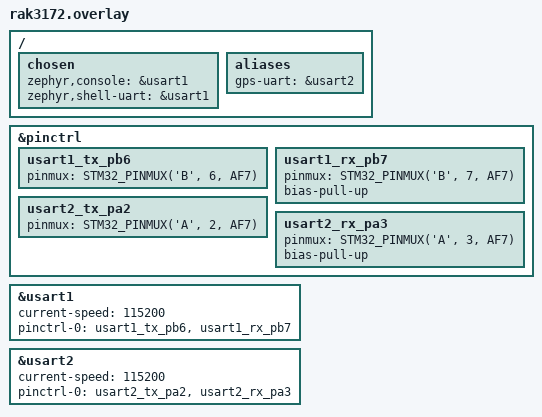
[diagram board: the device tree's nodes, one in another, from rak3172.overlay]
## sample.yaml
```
# Copyright (c) 2023 Trackunit Corporation
# SPDX-License-Identifier: Apache-2.0

sample:
  name: GNSS sample
tests:
  sample.drivers.gnss:
    tags:
      - drivers
      - gnss
    filter: dt_alias_exists("gnss")
    integration_platforms:
      - mimxrt1062_fmurt6
```

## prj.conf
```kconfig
# UART support for both console and GPS
CONFIG_SERIAL=y
CONFIG_UART_INTERRUPT_DRIVEN=y
CONFIG_CONSOLE=y
CONFIG_UART_CONSOLE=y

# Logging
CONFIG_LOG=y
CONFIG_LOG_BACKEND_UART=y

# System
CONFIG_MAIN_STACK_SIZE=4096
CONFIG_HEAP_MEM_POOL_SIZE=4096
```

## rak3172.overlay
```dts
/*
 * Dual UART setup:
 * USART1 (PB6/PB7): PC Console at 115200 baud
 * USART2 (PA2/PA3): GPS Module at 115200 baud
 */

/ {
    chosen {
        zephyr,console = &usart1;
        zephyr,shell-uart = &usart1;
    };
    
    aliases {
        gps-uart = &usart2;
    };
};

/* USART1 pinctrl for console (PB6/PB7) */
&pinctrl {
    usart1_tx_pb6: usart1_tx_pb6 {
        pinmux = <STM32_PINMUX('B', 6, AF7)>;
    };
    
    usart1_rx_pb7: usart1_rx_pb7 {
        pinmux = <STM32_PINMUX('B', 7, AF7)>;
        bias-pull-up;
    };
    
    /* USART2 pinctrl for GPS (PA2/PA3) */
    usart2_tx_pa2: usart2_tx_pa2 {
        pinmux = <STM32_PINMUX('A', 2, AF7)>;
    };
    
    usart2_rx_pa3: usart2_rx_pa3 {
        pinmux = <STM32_PINMUX('A', 3, AF7)>;
        bias-pull-up;
    };
};

/* USART1 for console */
&usart1 {
    status = "okay";
    current-speed = <115200>;
    pinctrl-0 = <&usart1_tx_pb6 &usart1_rx_pb7>;
    pinctrl-names = "default";
};

/* USART2 for GPS */
&usart2 {
    status = "okay";
    current-speed = <115200>;
    pinctrl-0 = <&usart2_tx_pa2 &usart2_rx_pa3>;
    pinctrl-names = "default";
};
```

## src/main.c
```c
/*
 * Dual UART Test for RAK3172
 * USART1 (PB6/PB7): Console to PC
 * USART2 (PA2/PA3): GPS communication
 */

#include <zephyr/kernel.h>
#include <zephyr/device.h>
#include <zephyr/drivers/uart.h>
#include <zephyr/drivers/gpio.h>
#include <zephyr/logging/log.h>

LOG_MODULE_REGISTER(dual_uart_test, LOG_LEVEL_INF);

/* LED setup if available */
#define LED0_NODE DT_ALIAS(led0)
static const struct gpio_dt_spec led = GPIO_DT_SPEC_GET_OR(LED0_NODE, gpios, {0});

/* GPS UART buffer */
static char gps_rx_buf[256];
static int gps_rx_buf_pos = 0;

static void gps_uart_rx_callback(const struct device *dev, void *user_data)
{
    uint8_t c;
    
    if (!uart_irq_update(dev)) {
        return;
    }
    
    if (!uart_irq_rx_ready(dev)) {
        return;
    }
    
    /* Read characters from GPS */
    while (uart_fifo_read(dev, &c, 1) == 1) {
        if (c == '\r' || c == '\n') {
            if (gps_rx_buf_pos > 0) {
                gps_rx_buf[gps_rx_buf_pos] = '\0';
                /* Print complete NMEA sentence to console */
                if (gps_rx_buf[0] == '$') {
                    LOG_INF("GPS: %s", gps_rx_buf);
                }
                gps_rx_buf_pos = 0;
            }
        } else if (gps_rx_buf_pos < (sizeof(gps_rx_buf) - 1)) {
            gps_rx_buf[gps_rx_buf_pos++] = c;
        }
    }
}

int main(void)
{
    const struct device *gps_uart;
    bool led_state = false;
    int counter = 0;
    
    /* Setup LED if available */
    if (gpio_is_ready_dt(&led)) {
        gpio_pin_configure_dt(&led, GPIO_OUTPUT_ACTIVE);
        LOG_INF("LED ready");
    }
    
    LOG_INF("=== RAK3172 Dual UART Test ===");
    LOG_INF("Console: USART1 (PB6/PB7) - you're seeing this!");
    LOG_INF("GPS:     USART2 (PA2/PA3) - will read NMEA data");
    
    /* Setup GPS UART */
    gps_uart = DEVICE_DT_GET(DT_ALIAS(gps_uart));
    if (!device_is_ready(gps_uart)) {
        LOG_ERR("GPS UART (USART2) not ready");
        return -ENODEV;
    }
    
    /* Configure GPS UART for interrupt-driven operation */
    uart_irq_callback_user_data_set(gps_uart, gps_uart_rx_callback, NULL);
    uart_irq_rx_enable(gps_uart);
    
    LOG_INF("GPS UART ready on USART2 (PA2/PA3)");
    LOG_INF("Connect LC86G: PA2→LC86G_RX, PA3→LC86G_TX, GND, 3V3");
    
    /* Send wake-up command to GPS */
    const char *wakeup_cmd = "$PAIR001*3C\r\n";
    uart_fifo_fill(gps_uart, (uint8_t*)wakeup_cmd, strlen(wakeup_cmd));
    LOG_INF("Sent wake-up command to GPS");
    
    LOG_INF("Starting main loop...");
    
    while (1) {
        /* Blink LED */
        if (gpio_is_ready_dt(&led)) {
            gpio_pin_set_dt(&led, led_state);
            led_state = !led_state;
        }
        
        counter++;
        LOG_INF("[%d] Console on USART1 working. Waiting for GPS data on USART2...", counter);
        
        if (counter % 10 == 0) {
            /* Send periodic command to GPS */
            const char *status_cmd = "$PAIR062*35\r\n";  // Query status
            uart_fifo_fill(gps_uart, (uint8_t*)status_cmd, strlen(status_cmd));
            LOG_INF("Sent status query to GPS");
        }
        
        k_sleep(K_SECONDS(3));
    }
    
    return 0;
}
```
